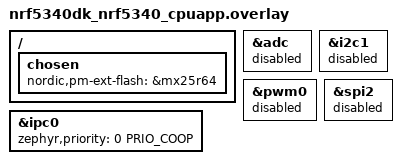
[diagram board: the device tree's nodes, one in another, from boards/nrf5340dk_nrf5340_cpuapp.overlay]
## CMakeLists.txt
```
#
# Copyright (c) 2023 Nordic Semiconductor ASA
#
# SPDX-License-Identifier: LicenseRef-Nordic-5-Clause
#

cmake_minimum_required(VERSION 3.20.0)

include($ENV{ZEPHYR_BASE}/../sidewalk/samples/common/bootloader_version.cmake)

set(mcuboot_KCONFIG_ROOT ${CMAKE_CURRENT_SOURCE_DIR}/child_image/mcuboot/Kconfig.root)
set(hci_rpmsg_KCONFIG_ROOT ${CMAKE_CURRENT_SOURCE_DIR}/child_image/hci_rpmsg/Kconfig.root)

find_package(Zephyr REQUIRED HINTS $ENV{ZEPHYR_BASE})
project(sidewalk_template)

zephyr_include_directories(include)

target_sources(app PRIVATE
    src/main.c
    src/application_thread.c
    src/board_events.c
    src/sidewalk_callbacks.c
)
```

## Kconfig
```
#
# Copyright (c) 2023 Nordic Semiconductor ASA
#
# SPDX-License-Identifier: LicenseRef-Nordic-5-Clause
#

config STATE_NOTIFIER_HANDLER_MAX
	default 3

config DELAY_BETWEN_MESSAGES
    int "delay in ms between messages"
    default 2000

config MESSAGES_TO_SEND
    int "number of messages to send during test"
    default 10

source "${ZEPHYR_BASE}/../sidewalk/samples/common/Kconfig.defconfig"
source "Kconfig.zephyr"
```

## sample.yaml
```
sample:
  name: Sidewalk application based on bel_only for power tests
  description: Sample that performs actions required for power measurements
tests:
  sidewalk.ble_only.test.power:
    build_only: true
    platform_allow: nrf52840dk_nrf52840 nrf5340dk_nrf5340_cpuapp
    extra_args: CONF_FILE=prj_release.conf
                OVERLAY_CONFIG=usb_dfu.conf
    integration_platforms:
      - nrf52840dk_nrf52840
      - nrf5340dk_nrf5340_cpuapp
    tags: Sidewalk
```

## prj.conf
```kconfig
#
# Copyright (c) 2023 Nordic Semiconductor ASA
#
# SPDX-License-Identifier: LicenseRef-Nordic-5-Clause
#

# Sidewalk
CONFIG_SIDEWALK=y

# Logs
CONFIG_SIDEWALK_LOG_LEVEL_INF=y
CONFIG_NVS_LOG_LEVEL_WRN=y
CONFIG_LOG_PRINTK=y

# Buttons and LEDs
CONFIG_GPIO=y
CONFIG_DK_LIBRARY=y

# Bluetooth
CONFIG_BT_DEVICE_NAME="Sid template"

# Debug
CONFIG_RESET_ON_FATAL_ERROR=n

# Power Management
CONFIG_PM=y
CONFIG_PM_DEVICE=y
```

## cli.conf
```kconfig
#
# Copyright (c) 2023 Nordic Semiconductor ASA
#
# SPDX-License-Identifier: LicenseRef-Nordic-5-Clause
#

CONFIG_SIDEWALK_CLI=y
```

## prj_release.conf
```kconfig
#
# Copyright (c) 2022 Nordic Semiconductor ASA
#
# SPDX-License-Identifier: LicenseRef-Nordic-5-Clause
#

# Sidewalk
CONFIG_SIDEWALK=y

# Buttons and LEDs
CONFIG_DK_LIBRARY=y

# Bluetooth
CONFIG_BT_DEVICE_NAME="Sid BLE template"

# Disable peripherals
CONFIG_LOG=n
CONFIG_SERIAL=n
CONFIG_SHELL=n
CONFIG_CONSOLE=n
CONFIG_UART_CONSOLE=n
CONFIG_ASSERT=n
CONFIG_ASSERT_VERBOSE=n
CONFIG_ASSERT_NO_FILE_INFO=y
CONFIG_PRINTK_SYNC=n
CONFIG_THREAD_NAME=n

# Power Management
CONFIG_PM=y
CONFIG_PM_DEVICE=y
```

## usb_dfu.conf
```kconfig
#
# Copyright (c) 2022 Nordic Semiconductor ASA
#
# SPDX-License-Identifier: LicenseRef-Nordic-5-Clause
#

CONFIG_SIDEWALK_DFU_SERVICE_USB=y


# Workaround for issue https://github.com/zephyrproject-rtos/zephyr/issues/53326
# Waiting for fix in upstream https://github.com/zephyrproject-rtos/zephyr/pull/53414
CONFIG_USB_DFU_WILL_DETACH=n
```

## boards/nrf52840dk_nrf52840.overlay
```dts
/*
 * Copyright (c) 2023 Nordic Semiconductor ASA
 *
 * SPDX-License-Identifier: LicenseRef-Nordic-5-Clause
 */

&mx25r64 {
	status = "disabled";
};
```

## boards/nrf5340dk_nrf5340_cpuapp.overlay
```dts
/*
 * Copyright (c) 2023 Nordic Semiconductor ASA
 *
 * SPDX-License-Identifier: LicenseRef-Nordic-5-Clause
 */

#include <zephyr/dt-bindings/ipc_service/static_vrings.h>

&ipc0 {
    zephyr,priority = <0 PRIO_COOP>;
};

/ {
	chosen {
		nordic,pm-ext-flash = &mx25r64;
	};
};

/* Disable unused peripherals to reduce power consumption */
&adc {
	status = "disabled";
};
&i2c1 {
	status = "disabled";
};
&pwm0 {
	status = "disabled";
};
&spi2 {
	status = "disabled";
};
```

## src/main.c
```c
/*
 * Copyright (c) 2023 Nordic Semiconductor ASA
 *
 * SPDX-License-Identifier: LicenseRef-Nordic-5-Clause
 */
#include <sid_api.h>
#include <sid_error.h>
#include <sid_pal_assert_ifc.h>
#include <app_ble_config.h>

#include <stdbool.h>
#include <zephyr/kernel.h>
#include <zephyr/logging/log.h>
#include <dk_buttons_and_leds.h>
#include <sidewalk_version.h>
#if defined(CONFIG_BOOTLOADER_MCUBOOT)
#include <zephyr/dfu/mcuboot.h>
#endif
#if defined(CONFIG_SIDEWALK_DFU_SERVICE_USB)
#include <zephyr/usb/usb_device.h>
#endif
#if defined(CONFIG_GPIO)
#include <state_notifier_gpio_backend.h>
#endif
#if defined(CONFIG_LOG)
#include <state_notifier_log_backend.h>
#endif

#include <pal_init.h>
#include <buttons.h>
#include <application_thread.h>
#include <sidewalk_callbacks.h>
#include <state_notifier.h>

#include <zephyr/settings/settings.h>

#if defined(CONFIG_NORDIC_QSPI_NOR)
#include <zephyr/device.h>
#include <zephyr/pm/device.h>

#define EXTERNAL_FLASH DT_CHOSEN(nordic_pm_ext_flash)
#endif

LOG_MODULE_REGISTER(sid_template, CONFIG_SIDEWALK_LOG_LEVEL);

bool factory_reset_bypass = false;

int alpha_handle_set(const char *name, size_t len, settings_read_cb read_cb, void *cb_arg);
int alpha_handle_export(int (*cb)(const char *name, const void *value, size_t val_len));

struct settings_handler alph_handler = { .name = "test",
					 .h_get = NULL,
					 .h_set = alpha_handle_set,
					 .h_commit = NULL,
					 .h_export = alpha_handle_export };

K_SEM_DEFINE(registered_sem, 0, 1);
K_SEM_DEFINE(not_sending_sem, 0, 1);
K_SEM_DEFINE(working_sem, 0, 1);
K_SEM_DEFINE(connected_sem, 0, 1);
K_SEM_DEFINE(time_sync_sem, 0, 1);
K_SEM_DEFINE(link_sem, 0, 1);

static app_ctx_t app_context;

volatile struct notifier_state current_app_state = {};

int alpha_handle_set(const char *name, size_t len, settings_read_cb read_cb, void *cb_arg)
{
	const char *next;

	if (settings_name_steq(name, "factory_reset_bypass", &next)) {
		if (len != sizeof(factory_reset_bypass)) {
			return -EINVAL;
		}
		read_cb(cb_arg, &factory_reset_bypass, sizeof(factory_reset_bypass));
		return 0;
	}
	return -ENOENT;
}

int alpha_handle_export(int (*cb)(const char *name, const void *value, size_t val_len))
{
	(void)cb("test/factory_reset_bypass", &factory_reset_bypass, sizeof(factory_reset_bypass));
	return 0;
}

void assert_post_action(const char *file, unsigned int line)
{
	LOG_ERR("Assert in %s:%d", file, line);

	k_panic();
}

static void button_handler(uint32_t event)
{
	app_event_send((app_event_t)event);
}

static sid_error_t app_buttons_init(btn_handler_t handler)
{
	button_set_action_long_press(DK_BTN1, handler, BUTTON_EVENT_FACTORY_RESET);
	button_set_action(DK_BTN2, handler, BUTTON_EVENT_CONNECTION_REQUEST);
	button_set_action(DK_BTN3, handler, BUTTON_EVENT_SEND_HELLO);
	button_set_action_short_press(DK_BTN4, handler, BUTTON_EVENT_SET_BATTERY_LEVEL);
#if defined(CONFIG_SIDEWALK_DFU)
	button_set_action_long_press(DK_BTN4, handler, BUTTON_EVENT_NORDIC_DFU);
#endif

	return buttons_init() ? SID_ERROR_GENERIC : SID_ERROR_NONE;
}

static void app_setup(void)
{
	if (app_buttons_init(button_handler)) {
		LOG_ERR("Failed to initialze buttons.");
		SID_PAL_ASSERT(false);
	}

	if (dk_leds_init()) {
		LOG_ERR("Failed to initialze LEDs.");
		SID_PAL_ASSERT(false);
	}
#if defined(CONFIG_GPIO)
	state_watch_init_gpio(&global_state_notifier);
#endif
#if defined(CONFIG_LOG)
	state_watch_init_log(&global_state_notifier);
#endif

#if defined(CONFIG_SIDEWALK_DFU_SERVICE_USB)
	if (usb_enable(NULL)) {
		LOG_ERR("Failed to enable USB");
		return;
	}
#endif

	if (sidewalk_callbacks_set(&app_context, &app_context.event_callbacks)) {
		LOG_ERR("Failed to set sidewalk callbacks");
		SID_PAL_ASSERT(false);
	}

	app_context.config = (struct sid_config){
		.link_mask = BUILT_IN_LM,
		.time_sync_periodicity_seconds = 7200,
		.callbacks = &app_context.event_callbacks,
		.link_config = app_get_ble_config(),
		.sub_ghz_link_config = NULL,
	};

#if defined(CONFIG_BOOTLOADER_MCUBOOT)
	if (!boot_is_img_confirmed()) {
		int ret = boot_write_img_confirmed();

		if (ret) {
			LOG_ERR("Couldn't confirm image: %d", ret);
		} else {
			LOG_INF("Marked image as OK");
		}
	}
#endif

#if (defined(CONFIG_NORDIC_QSPI_NOR) && defined(NRF5340_XXAA))
	const struct device *const qspi_dev = DEVICE_DT_GET(EXTERNAL_FLASH);

	if (device_is_ready(qspi_dev)) {
		pm_device_action_run(qspi_dev, PM_DEVICE_ACTION_SUSPEND);
	}
#endif
}

static void state_change_handler_power_test(const struct notifier_state *state)
{
	current_app_state = *state;
	if (current_app_state.registered) {
		k_sem_give(&registered_sem);
	}
	if (current_app_state.sending == 0) {
		k_sem_give(&not_sending_sem);
	} else {
		k_sem_reset(&not_sending_sem);
	}
	if (current_app_state.connected) {
		k_sem_give(&connected_sem);
	} else {
		k_sem_reset(&connected_sem);
	}
	if (current_app_state.time_sync) {
		k_sem_give(&time_sync_sem);
	} else {
		k_sem_reset(&time_sync_sem);
	}
	if (current_app_state.working) {
		k_sem_give(&working_sem);
	}
	if (current_app_state.link) {
		k_sem_give(&link_sem);
	} else {
		k_sem_reset(&link_sem);
	}
}

void wait_for_registered()
{
	LOG_INF("%s", __func__);
	if (!current_app_state.registered) {
		k_sem_take(&registered_sem, K_FOREVER);
	}
}

void wait_for_not_sending()
{
	LOG_INF("%s", __func__);
	if (current_app_state.sending) {
		while (0 != k_sem_take(&not_sending_sem, K_FOREVER)) {
		};
	}
}

void wait_for_connected()
{
	LOG_INF("%s", __func__);
	if (!current_app_state.connected) {
		while (0 != k_sem_take(&connected_sem, K_FOREVER)) {
		};
	}
}

void wait_for_time_sync()
{
	LOG_INF("%s", __func__);
	if (!current_app_state.time_sync) {
		while (0 != k_sem_take(&time_sync_sem, K_FOREVER)) {
		};
	}
}

void wait_for_link()
{
	LOG_INF("%s", __func__);
	if (!current_app_state.link) {
		while (0 != k_sem_take(&link_sem, K_FOREVER)) {
		};
	}
}

static inline void perform_power_test(void)
{
	LOG_INF("%s", __func__);
	wait_for_registered();
	wait_for_time_sync();
	wait_for_not_sending();

	for (int i = 0; i < CONFIG_MESSAGES_TO_SEND; i++) {
		if (!current_app_state.connected) {
			wait_for_registered();
			wait_for_time_sync();
			app_event_send(BUTTON_EVENT_CONNECTION_REQUEST);
			wait_for_connected();
		}

		wait_for_connected();
		wait_for_not_sending();
		k_sleep(K_MSEC(CONFIG_DELAY_BETWEN_MESSAGES));
		app_event_send(BUTTON_EVENT_SEND_HELLO);
	}
}

int main(void)
{
	PRINT_SIDEWALK_VERSION();

	extern struct notifier_ctx global_state_notifier;

	if (!subscribe_for_state_change(&global_state_notifier, state_change_handler_power_test)) {
		__ASSERT(
			false,
			"failed to initialize the state watch, is the CONFIG_STATE_NOTIFIER_HANDLER_MAX too low ?");
	}

	app_setup();
	if (app_thread_init(&app_context)) {
		LOG_ERR("Failed to start Sidewalk thread");
	}

	if (!current_app_state.working) {
		k_sem_take(&working_sem, K_FOREVER);
	}

	settings_subsys_init();
	settings_register(&alph_handler);
	settings_load();

	if (factory_reset_bypass == false) {
		factory_reset_bypass = true;
		settings_save();
		settings_commit();

		LOG_INF("Perform factory reset");
		k_sleep(K_SECONDS(1));
		app_event_send(BUTTON_EVENT_FACTORY_RESET);
		k_sleep(K_FOREVER);
	}
	factory_reset_bypass = false;
	settings_save();
	settings_commit();

	perform_power_test();

	return 0;
}
```

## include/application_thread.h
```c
/*
 * Copyright (c) 2023 Nordic Semiconductor ASA
 *
 * SPDX-License-Identifier: LicenseRef-Nordic-5-Clause
 */

#ifndef APPLICATION_THREAD_H
#define APPLICATION_THREAD_H

#include <sid_api.h>

#ifdef CONFIG_SIDEWALK_LINK_MASK_BLE
#define BUILT_IN_LM             (uint32_t)(SID_LINK_TYPE_1)
#elif  CONFIG_SIDEWALK_LINK_MASK_FSK
#define BUILT_IN_LM             (uint32_t)(SID_LINK_TYPE_2)
#elif CONFIG_SIDEWALK_LINK_MASK_LORA
#define BUILT_IN_LM             (uint32_t)(SID_LINK_TYPE_3)
#else
#error "Not defined Sidewalk link mask!!"
#endif

typedef struct application_context {
	struct sid_event_callbacks event_callbacks;
	struct sid_config config;
	struct sid_handle *handle;
	bool connection_request;
} app_ctx_t;

typedef enum application_events {
	SIDEWALK_EVENT,

	BUTTON_EVENT_SEND_HELLO,
	BUTTON_EVENT_SET_BATTERY_LEVEL,
	BUTTON_EVENT_FACTORY_RESET,
	BUTTON_EVENT_CONNECTION_REQUEST,
	#if  defined(CONFIG_SIDEWALK_DFU)
	BUTTON_EVENT_NORDIC_DFU,
	#endif
} app_event_t;

/**
 * @brief Send Event to application thread
 *
 * @param event event to send
 */
void app_event_send(app_event_t event);

/**
 * @brief Initialize and start application thread
 *
 * @param ctx application context
 *
 * @return SID_ERROR_NULL_POINTER in case of invalid ctx
 */
sid_error_t app_thread_init(app_ctx_t *ctx);

#endif /* APPLICATION_THREAD_H */
```

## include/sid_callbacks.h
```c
/*
 * Copyright (c) 2023 Nordic Semiconductor ASA
 *
 * SPDX-License-Identifier: LicenseRef-Nordic-4-Clause
 */
#ifndef SID_CALLBACKS_H
#define SID_CALLBACKS_H
 #include <sid_api.h>
 
/**
 * @brief This function sets callbacks which will be invoked Sidewalk events occurs.
 *
 * @param ctx current user context.
 * @param cb pointer to object which stores callbacks.
 * @return 0 when success or negative value otherwise.
 */
int sid_callbacks_set(void *ctx, struct sid_event_callbacks *cb);

#endif /* SID_CALLBACKS_H */
```

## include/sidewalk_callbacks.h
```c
/*
 * Copyright (c) 2023 Nordic Semiconductor ASA
 *
 * SPDX-License-Identifier: LicenseRef-Nordic-5-Clause
 */

#ifndef SIDEWALK_CALLBACKS_H
#define SIDEWALK_CALLBACKS_H

#include <sid_api.h>

/**
 * @brief Initialize sidewalk callbacks
 *
 * @param context Application context passed to callbacks
 * @param callbacks [out] callbacks to set
 * @returns #SID_ERROR_NONE in case of success negative error code otherwise.
 */
sid_error_t sidewalk_callbacks_set(void *context, struct sid_event_callbacks *callbacks);

#endif /* SIDEWALK_CALLBACKS_H */
```

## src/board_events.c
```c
/*
 * Copyright (c) 2023 Nordic Semiconductor ASA
 *
 * SPDX-License-Identifier: LicenseRef-Nordic-5-Clause
 */

#include <sid_api.h>
#include <sid_error.h>

#include <state_notifier.h>
#include <board_events.h>

#if defined(CONFIG_SIDEWALK_DFU)
#include <nordic_dfu.h>
#endif

#include <zephyr/logging/log.h>

LOG_MODULE_REGISTER(board_events, CONFIG_SIDEWALK_LOG_LEVEL);

void button_event_send_hello(app_ctx_t *application_ctx)
{
	struct sid_status status = { .state = SID_STATE_NOT_READY };
	sid_error_t err;

	static uint8_t counter = 0;
	static struct sid_msg msg;
	static struct sid_msg_desc desc;

	err = sid_get_status(application_ctx->handle, &status);
	switch (err) {
	case SID_ERROR_NONE:
		break;
	case SID_ERROR_INVALID_ARGS:
		LOG_ERR("Sidewalk library is not initialzied!");
		return;
	default:
		LOG_ERR("Unknown error during sid_get_status() -> %d", err);
		return;
	}

	if (status.state != SID_STATE_READY && status.state != SID_STATE_SECURE_CHANNEL_READY) {
		LOG_ERR("Sidewalk Status is invalid!, expected SID_STATE_READY or SID_STATE_SECURE_CHANNEL_READY, got %d",
			status.state);
		return;
	}

	msg = (struct sid_msg){ .data = (uint8_t *)&counter, .size = sizeof(uint8_t) };
	desc = (struct sid_msg_desc){
		.type = SID_MSG_TYPE_NOTIFY,
		.link_type = SID_LINK_TYPE_ANY,
		.link_mode = SID_LINK_MODE_CLOUD,
	};

	err = sid_put_msg(application_ctx->handle, &msg, &desc);
	switch (err) {
	case SID_ERROR_NONE: {
		application_state_sending(&global_state_notifier, true);
		counter++;
		LOG_INF("queued data message id:%d", desc.id);
		break;
	}
	case SID_ERROR_TRY_AGAIN: {
		LOG_ERR("there is no space in the transmit queue, Try again.");
		break;
	}
	default:
		LOG_ERR("Unknown error returned from sid_put_msg() -> %d", err);
	}
}

void button_event_set_battery(app_ctx_t *application_ctx)
{
	static uint8_t fake_bat_lev = 70;

	++fake_bat_lev;
	if (fake_bat_lev > 100) {
		fake_bat_lev = 0;
	}
	sid_error_t ret = sid_option(application_ctx->handle, SID_OPTION_BLE_BATTERY_LEVEL,
				     &fake_bat_lev, sizeof(fake_bat_lev));

	if (SID_ERROR_NONE != ret) {
		LOG_ERR("failed setting Sidewalk option!");
	} else {
		LOG_DBG("set battery level to %d", fake_bat_lev);
	}
}

#if defined(CONFIG_SIDEWALK_DFU_SERVICE_BLE)
void button_event_DFU(app_ctx_t *application_ctx)
{
	sid_error_t err = sid_deinit(application_ctx->handle);

	if (err != SID_ERROR_NONE) {
		LOG_ERR("Failed to deinitialize sidewalk! sid_deinit returned %d", err);
		return;
	}

	application_ctx->handle = NULL;

	int ret = nordic_dfu_ble_start();

	if (ret) {
		LOG_ERR("DFU SMP start error (code %d)", ret);
	}
	application_state_dfu(&global_state_notifier, true);
}

#endif

void button_event_factory_reset(app_ctx_t *application_ctx)
{
	sid_error_t ret = sid_set_factory_reset(application_ctx->handle);

	if (SID_ERROR_NONE != ret) {
		LOG_ERR("Notification of factory reset to sid api failed!");
	} else {
		LOG_DBG("Wait for Sid api to notify to proceed with factory reset!");
	}
}

void button_event_connection_request(app_ctx_t *application_ctx)
{
	struct sid_status status = { .state = SID_STATE_NOT_READY };
	sid_error_t err = sid_get_status(application_ctx->handle, &status);

	switch (err) {
	case SID_ERROR_NONE:
		break;
	case SID_ERROR_INVALID_ARGS:
		LOG_ERR("Sidewalk library is not initialzied!");
		return;
	default:
		LOG_ERR("Unknown error during sid_get_status() -> %d", err);
		return;
	}

	if (status.state == SID_STATE_READY) {
		LOG_WRN("Sidewalk ready, operation not valid");
		return;
	}

	bool next = !application_ctx->connection_request;

	LOG_INF("%s connection request", next ? "Set" : "Clear");
	sid_error_t ret = sid_ble_bcn_connection_request(application_ctx->handle, next);

	if (SID_ERROR_NONE == ret) {
		application_ctx->connection_request = next;
	} else {
		LOG_ERR("Connection request failed %d", ret);
	}
}
```

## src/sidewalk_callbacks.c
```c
/*
 * Copyright (c) 2023 Nordic Semiconductor ASA
 *
 * SPDX-License-Identifier: LicenseRef-Nordic-5-Clause
 */

#include <sid_api.h>
#include <sid_error.h>
#include <sid_hal_reset_ifc.h>

#include <state_notifier.h>
#if defined(CONFIG_SIDEWALK_CLI)
#include <sid_shell.h>
#endif

#include <application_thread.h>

#include <zephyr/logging/log.h>

LOG_MODULE_REGISTER(callbacks, CONFIG_SIDEWALK_LOG_LEVEL);

static const uint8_t *status_name[] = { "ready", "not ready", "Error", "secure channel ready" };

static const uint8_t *link_mode_idx_name[] = { "ble", "fsk", "lora" };

static void on_sidewalk_event(bool in_isr, void *context)
{
	LOG_DBG("on event, from %s, context %p", in_isr ? "ISR" : "App", context);
	app_event_send(SIDEWALK_EVENT);
}

static void on_sidewalk_msg_received(const struct sid_msg_desc *msg_desc, const struct sid_msg *msg,
				     void *context)
{
#ifdef CONFIG_SIDEWALK_CLI
	CLI_register_message_received(msg_desc->id);
#endif
	application_state_receiving(&global_state_notifier, true);
	application_state_receiving(&global_state_notifier, false);
	LOG_DBG("received message(type: %d, link_mode: %d, id: %u size %u)", (int)msg_desc->type,
		(int)msg_desc->link_mode, msg_desc->id, msg->size);
	LOG_HEXDUMP_INF((uint8_t *)msg->data, msg->size, "Message data: ");
}

static void on_sidewalk_msg_sent(const struct sid_msg_desc *msg_desc, void *context)
{
	application_state_sending(&global_state_notifier, false);
#ifdef CONFIG_SIDEWALK_CLI
	CLI_register_message_send();
#endif
	LOG_INF("sent message(type: %d, id: %u)", (int)msg_desc->type, msg_desc->id);
}

static void on_sidewalk_send_error(sid_error_t error, const struct sid_msg_desc *msg_desc,
				   void *context)
{
	application_state_sending(&global_state_notifier, false);
#ifdef CONFIG_SIDEWALK_CLI
	CLI_register_message_not_send();
#endif
	LOG_ERR("failed to send message(type: %d, id: %u), err:%d", (int)msg_desc->type,
		msg_desc->id, (int)error);
}

static void on_sidewalk_status_changed(const struct sid_status *status, void *context)
{
	LOG_INF("status changed: %s", status_name[status->state]);

	app_ctx_t *app_ctx = (app_ctx_t *)context;

#ifdef CONFIG_SIDEWALK_CLI
	CLI_register_sid_status(status);
#endif
	switch (status->state) {
	case SID_STATE_READY:
		application_state_connected(&global_state_notifier, true);
		app_ctx->connection_request = false;
		break;
	case SID_STATE_NOT_READY:
		application_state_connected(&global_state_notifier, false);
		break;
	case SID_STATE_ERROR:
		LOG_ERR("Sidewalk error: %d", (int)sid_get_error(app_ctx->handle));
		break;
	case SID_STATE_SECURE_CHANNEL_READY:
		break;
	}

	application_state_registered(&global_state_notifier,
				     status->detail.registration_status == SID_STATUS_REGISTERED);
	application_state_time_sync(&global_state_notifier,
				    status->detail.time_sync_status == SID_STATUS_TIME_SYNCED);
	application_state_link(&global_state_notifier, !!(status->detail.link_status_mask));

	LOG_INF("Device %sregistered, Time Sync %s, Link status: {BLE: %s, LORA: %s, FSK: %s}",
		(SID_STATUS_REGISTERED == status->detail.registration_status) ? "Is " : "Un",
		(SID_STATUS_TIME_SYNCED == status->detail.time_sync_status) ? "Success" : "Fail",
		(status->detail.link_status_mask & SID_LINK_TYPE_1) ? "Up" : "Down",
		(status->detail.link_status_mask & SID_LINK_TYPE_2) ? "Up" : "Down",
		(status->detail.link_status_mask & SID_LINK_TYPE_3) ? "Up" : "Down");

	for (int i = 0; i < SID_LINK_TYPE_MAX_IDX; i++) {
		enum sid_link_mode mode =
			(enum sid_link_mode)status->detail.supported_link_modes[i];

		if (mode) {
			LOG_INF("Link mode on %s = {Cloud: %s, Mobile: %s}", link_mode_idx_name[i],
				(mode & SID_LINK_MODE_CLOUD) ? "True" : "False",
				(mode & SID_LINK_MODE_MOBILE) ? "True" : "False");
		}
	}
}

static void on_sidewalk_factory_reset(void *context)
{
	ARG_UNUSED(context);

	LOG_INF("factory reset notification received from sid api");
	if (sid_hal_reset(SID_HAL_RESET_NORMAL)) {
		LOG_WRN("Reboot type not supported");
	}
}

sid_error_t sidewalk_callbacks_set(void *context, struct sid_event_callbacks *callbacks)
{
	if (!callbacks) {
		return SID_ERROR_INVALID_ARGS;
	}
	callbacks->context = context;
	callbacks->on_event = on_sidewalk_event;
	callbacks->on_msg_received = on_sidewalk_msg_received; /* Called from sid_process() */
	callbacks->on_msg_sent = on_sidewalk_msg_sent; /* Called from sid_process() */
	callbacks->on_send_error = on_sidewalk_send_error; /* Called from sid_process() */
	callbacks->on_status_changed = on_sidewalk_status_changed; /* Called from sid_process() */
	callbacks->on_factory_reset = on_sidewalk_factory_reset; /* Called from sid_process() */

	return SID_ERROR_NONE;
}
```
